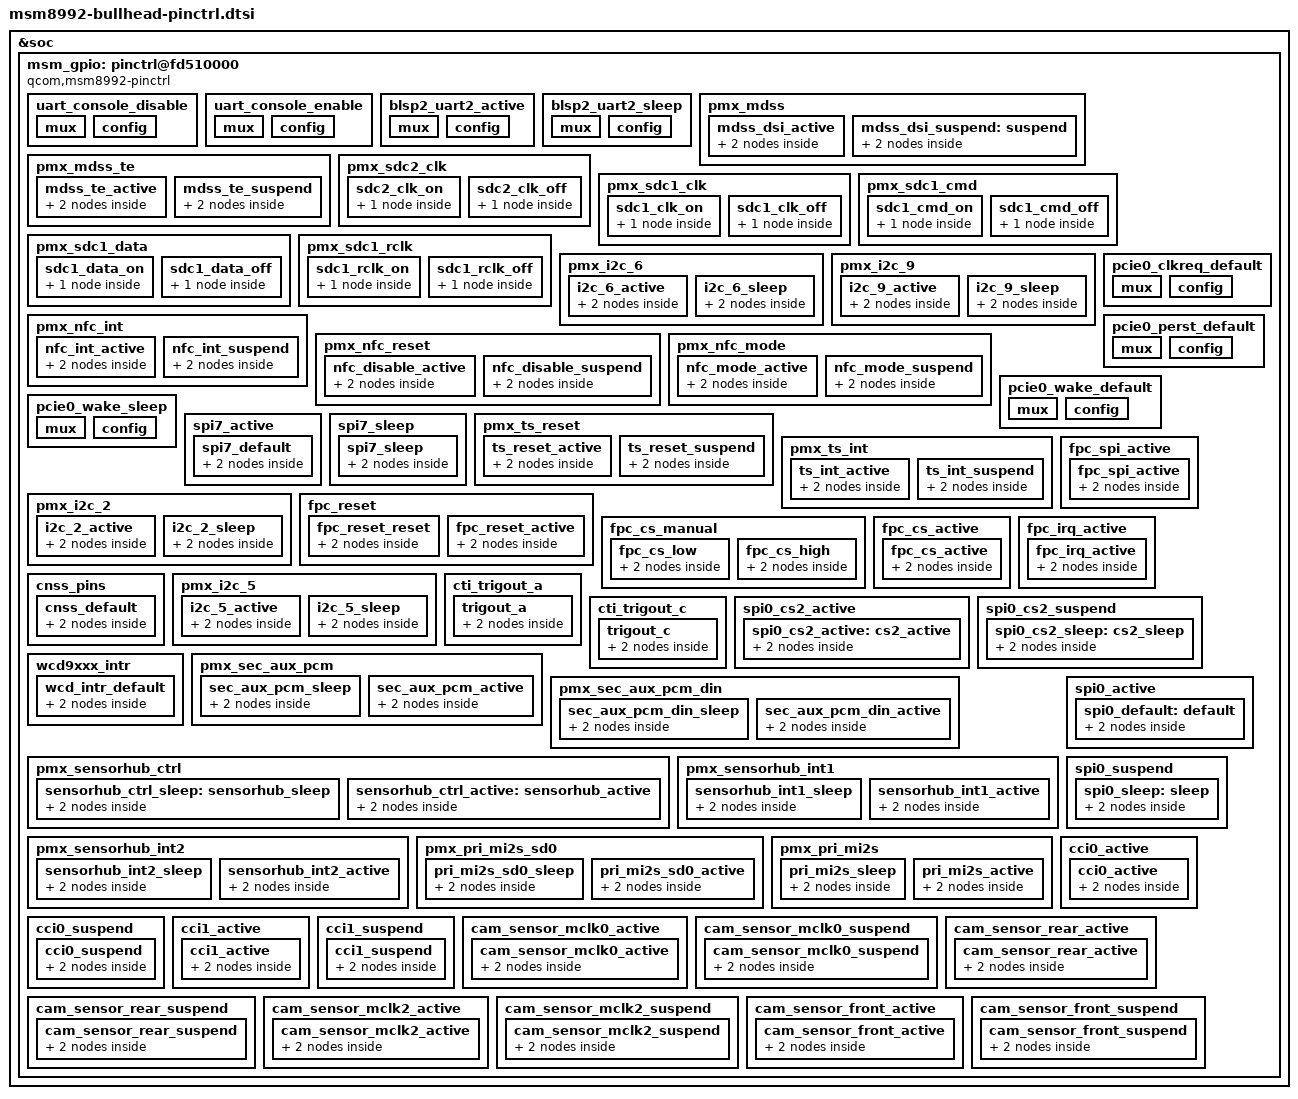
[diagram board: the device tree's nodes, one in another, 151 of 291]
/* Copyright (c) 2015, LGE Inc. All rights reserved.
 * Copyright (c) 2013-2015, The Linux Foundation. All rights reserved.
 *
 * This program is free software; you can redistribute it and/or modify
 * it under the terms of the GNU General Public License version 2 and
 * only version 2 as published by the Free Software Foundation.
 *
 * This program is distributed in the hope that it will be useful,
 * but WITHOUT ANY WARRANTY; without even the implied warranty of
 * MERCHANTABILITY or FITNESS FOR A PARTICULAR PURPOSE.  See the
 * GNU General Public License for more details.
 */

&soc {
	msm_gpio: pinctrl@fd510000 {
		compatible = "qcom,msm8992-pinctrl";
		reg = <0xfd510000 0x4000>;
		interrupts = <0 208 0>;
		gpio-controller;
		#gpio-cells = <2>;
		interrupt-controller;
		#interrupt-cells = <2>;

		uart_console_disable: uart_console_disable {
			mux {
				pins = "gpio4", "gpio5";
				function = "blsp_uart2";
			};

			config {
				pins = "gpio4", "gpio5";
				drive-strength = <2>; /* 2 mA */
				bias-disable; /* No PULL */
			};
		};

		uart_console_enable: uart_console_enable {
			mux {
				pins = "gpio4", "gpio5";
				function = "blsp_uart2";
			};

			config {
				pins = "gpio4", "gpio5";
				drive-strength = <2>; /* 2 mA */
				bias-disable; /* No PULL */
			};
		};


		blsp2_uart2_active: blsp2_uart2_active {
			mux {
				pins = "gpio45", "gpio46", "gpio47", "gpio48";
				function = "gpio";
			};

			config {
				pins = "gpio45", "gpio46", "gpio47", "gpio48";
				drive-strength = <16>; /* 16 mA */
				bias-disable; /* No PULL */
			};
		};

		blsp2_uart2_sleep: blsp2_uart2_sleep {
			mux {
				pins = "gpio45", "gpio46", "gpio47", "gpio48";
				function = "gpio";
			};

			config {
				pins = "gpio45", "gpio46", "gpio47", "gpio48";
				drive-strength = <2>; /* 2 mA */
				bias-disable; /* No PULL */
			};
		};


		pmx_mdss {
			mdss_dsi_active: mdss_dsi_active {
				mux {
					pins = "gpio78", "gpio89", "gpio90";
					function = "gpio";
				};

				config {
					pins = "gpio78", "gpio89", "gpio90";
					drive-strength = <8>; /* 8 mA */
					bias-disable; /* No PULL */
				};
			};

			mdss_dsi_suspend: suspend {
				mux {
					pins = "gpio78", "gpio89", "gpio90";
					function = "gpio";
				};

				config {
					pins = "gpio78", "gpio89", "gpio90";
					drive-strength = <2>; /* 2 mA */
					bias-pull-down; /* PULL DOWN */
				};
			};
		};

		pmx_mdss_te {
			mdss_te_active: mdss_te_active {
				mux {
					pins = "gpio10";
					function = "mdp_vsync";
				};

				config {
					pins = "gpio10";
					drive-strength = <2>; /* 2 mA */
					bias-pull-down = <0>; /* PULL DOWN */
				};
			};

			mdss_te_suspend: mdss_te_suspend {
				mux {
					pins = "gpio10";
					function = "mdp_vsync";
				};

				config {
					pins = "gpio10";
					drive-strength = <2>; /* 2 mA */
					bias-pull-down; /* PULL DOWN */
				};
			};
		};

		pmx_sdc2_clk {
			sdc2_clk_on: sdc2_clk_on {
				config {
					pins = "sdc2_clk";
					drive-strength = <16>; /* 10 mA */
					bias-disable; /* No PULL */
				};
			};
			sdc2_clk_off: sdc2_clk_off {
				config {
					pins = "sdc2_clk";
					drive-strength = <2>; /* 2 mA */
					bias-disable; /* No PULL */
				};
			};
		};

		pmx_sdc1_clk {
			sdc1_clk_on: sdc1_clk_on {
				config {
					pins = "sdc1_clk";
					drive-strength = <16>; /* 16 mA */
					bias-disable; /* No PULL */
				};
			};

			sdc1_clk_off: sdc1_clk_off {
				config {
					pins = "sdc1_clk";
					drive-strength = <2>; /* 2 mA */
					bias-disable; /* No PULL */
				};
			};
		};

		pmx_sdc1_cmd {
			sdc1_cmd_on: sdc1_cmd_on {
				config {
					pins = "sdc1_cmd";
					bias-pull-up; /* PULL UP */
					drive-strength = <8>; /* 8 mA */
				};
			};

			sdc1_cmd_off: sdc1_cmd_off {
				config {
					pins = "sdc1_cmd";
					bias-pull-up = <0x3>; /* PULL UP */
					drive-strength = <2>; /* 2 mA */
				};
			};
		};

		pmx_sdc1_data {
			sdc1_data_on: sdc1_data_on {
				config {
					pins = "sdc1_data";
					bias-pull-up; /* PULL UP */
					drive-strength = <8>; /* 10 mA */
				};
			};

			sdc1_data_off: sdc1_data_off {
				config {
					pins = "sdc1_data";
					bias-pull-up; /* PULL UP */
					drive-strength = <2>; /* 2 mA */
				};
			};
		};

		pmx_sdc1_rclk {
			sdc1_rclk_on: sdc1_rclk_on {
				config {
					pins = "sdc1_rclk";
					bias-pull-down; /* PULL DOWN */
				};
			};

			sdc1_rclk_off: sdc1_rclk_off {
				config {
					pins = "sdc1_rclk";
					bias-pull-down; /* PULL DOWN */
				};
			};
		};

		pmx_i2c_6 {
			i2c_6_active: i2c_6_active {
				mux {
					pins = "gpio27", "gpio28";
					function = "blsp_i2c6";
				};

				config {
					pins = "gpio27", "gpio28";
					drive-strength = <2>; /* 2 mA */
					bias-disable; /* No PULL */
				};
			};

			i2c_6_sleep: i2c_6_sleep {
				mux {
					pins = "gpio27", "gpio28";
					function = "blsp_i2c6";
				};

				config {
					pins = "gpio27", "gpio28";
					drive-strength = <2>; /* 2 mA */
					bias-disable; /* No PULL */
				};
			};

		};

		pmx_i2c_9 {
			i2c_9_active: i2c_9_active {
				mux {
					pins = "gpio51", "gpio52";
					function = "blsp_i2c9";
				};

				config {
					pins = "gpio51", "gpio52";
					drive-strength = <2>; /* 2 mA */
					bias-disable; /* No PULL */
				};
			};

			i2c_9_sleep: i2c_9_sleep {
				mux {
					pins = "gpio51", "gpio52";
					function = "blsp_i2c9";
				};

				config {
					pins = "gpio51", "gpio52";
					drive-strength = <2>; /* 2 mA */
					bias-disable; /* No PULL */
				};
			};

		};

		pmx_nfc_int {
			nfc_int_active: nfc_int_active {
				mux {
					pins = "gpio29";
					function = "gpio";
				};

				config {
					drive-strength = <2>; /* 2 mA */
					bias-disable; /* No PULL */
				};
			};

			nfc_int_suspend: nfc_int_suspend {
				mux {
					pins = "gpio29";
					function = "gpio";
				};

				config {
					drive-strength = <2>; /* 2 mA */
					bias-disable; /* No PULL */
				};
			};
		};

		pmx_nfc_reset {
			nfc_disable_active: nfc_disable_active {
				mux {
					pins = "gpio30";
					function = "gpio";
				};

				config {
					drive-strength = <2>; /* 2 mA */
					bias-pull-up; /* PULL UP */
				};
			};

			nfc_disable_suspend: nfc_disable_suspend {
				mux {
					pins = "gpio30";
					function = "gpio";
				};

				config {
					drive-strength = <2>; /* 2 mA */
					bias-disable; /* No PULL */
				};
			};
		};

		pmx_nfc_mode {
			nfc_mode_active: nfc_mode_active {
				mux {
					pins = "gpio39";
					function = "gpio";
				};

				config {
					drive-strength = <2>; /* 2 mA */
					bias-disable; /* No PULL */
				};
			};

			nfc_mode_suspend: nfc_mode_suspend {
				mux {
					pins = "gpio39";
					function = "gpio";
				};

				config {
					drive-strength = <2>; /* 2 mA */
					bias-disable; /* No PULL */
				};
			};
		};

		pcie0_clkreq_default: pcie0_clkreq_default {
			mux {
				pins = "gpio36";
				function = "pci_e1";
			};

			config {
				pins = "gpio36";
				drive-strength = <2>; /* 2 mA */
				bias-pull-up; /* PULL UP */
			};
		};

		pcie0_perst_default: pcie0_perst_default {
			mux {
				pins = "gpio35";
				function = "gpio";
			};

			config {
				pins = "gpio35";
				drive-strength = <2>; /* 2 mA */
				bias-pull-down; /* PULL DOWN */
			};
		};

		pcie0_wake_default: pcie0_wake_default {
			mux {
				pins = "gpio37";
				function = "gpio";
			};

			config {
				pins = "gpio37";
				drive-strength = <2>; /* 2 mA */
				bias-pull-down; /* PULL DOWN */
			};
		};

		pcie0_wake_sleep: pcie0_wake_sleep {
			mux {
				pins = "gpio37";
				function = "gpio";
			};

			config {
				pins = "gpio37";
				drive-strength = <2>; /* 2 mA */
				bias-disable; /* No PULL */
			};
		};


		spi7_active {
			spi7_default: spi7_default {
				mux {
					pins = "gpio41", "gpio42", "gpio44";
					function = "blsp_spi7";
				};

				config {
					pins = "gpio41", "gpio42", "gpio44";
					drive-strength = <12>; /* 12 mA */
					bias-disable; /* No PULL */
				};
			};
		};

		spi7_sleep {
			spi7_sleep: spi7_sleep {
				mux {
					pins = "gpio41", "gpio42", "gpio44";
					function = "blsp_spi7";
				};

				config {
					pins = "gpio41", "gpio42", "gpio44";
					drive-strength = <2>; /* 2 mA */
					bias-pull-down; /* PULL DOWN */
				};
			};
		};

		pmx_ts_reset {
			ts_reset_active: ts_reset_active {
				mux {
					pins = "gpio8";
					function = "gpio";
				};

				config {
					pins = "gpio8";
					drive-strength = <2>; /* 2 mA */
					bias-disable; /* No PULL */
				};
			};

			ts_reset_suspend: ts_reset_suspend {
				mux {
					pins = "gpio8";
					function = "gpio";
				};

				config {
					pins = "gpio8";
					drive-strength = <2>; /* 2 mA */
					bias-disable; /* No PULL */
				};
			};
		};

		pmx_ts_int {
			ts_int_active: ts_int_active {
				mux {
					pins = "gpio22";
					function = "gpio";
				};

				config {
					pins = "gpio22";
					drive-strength = <2>; /* 2 mA */
					bias-disable; /* No PULL */
				};
			};

			ts_int_suspend: ts_int_suspend {
				mux {
					pins = "gpio22";
					function = "gpio";
				};

				config {
					pins = "gpio22";
					drive-strength = <2>; /* 2 mA */
					bias-disable; /* No PULL */
				};
			};
		};

		pmx_i2c_2 {
			i2c_2_active: i2c_2_active {
				mux {
					pins = "gpio6", "gpio7";
					function = "blsp_i2c2";
				};

				config {
					pins = "gpio6", "gpio7";
					drive-strength = <6>; /* 6 mA */
					bias-disable; /* No PULL */
				};
			};

			i2c_2_sleep: i2c_2_sleep {
				mux {
					pins = "gpio6", "gpio7";
					function = "blsp_i2c2";
				};

				config {
					pins = "gpio6", "gpio7";
					drive-strength = <2>; /* 2 mA */
					bias-disable; /* No PULL */
				};
			};
		};

		fpc_spi_active {
			fpc_spi_active: fpc_spi_active {
				mux {
					pins =  "gpio53", "gpio54", "gpio55", "gpio56";
					function = "blsp_spi10";
				};

				config {
					pins =  "gpio53", "gpio54", "gpio55", "gpio56";
					drive-strength = <2>; /* 2 mA */
					bias-disable; /* No PULl */
				};
			};
		};

		fpc_reset {
			fpc_reset_reset: fpc_reset_reset {
				mux {
					pins = "gpio62";
					function = "blsp_spi2_cs1";
				};

				config {
					pins = "gpio62";
					drive-strength = <12>; /* 12 mA */
					bias-pull-down; /* PULL DOWN */
					output-low;
				};
			};

			fpc_reset_active: fpc_reset_active {
				mux {
					pins = "gpio62";
					function = "blsp_spi2_cs1";
				};

				config {
					pins = "gpio62";
					drive-strength = <12>; /* 12 mA */
					bias-pull-down; /* PULL DOWN */
					output-high;
				};
			};

		};

		fpc_cs_manual {
			fpc_cs_low: fpc_cs_low {
				mux {
					pins = "gpio55";
					function = "gpio";
				};

				config {
					pins = "gpio55";
					drive-strength = <1>; /* 1 mA */
					bias-pull-down; /* PULL DOWN */
					output-low;
				};
			};

			fpc_cs_high: fpc_cs_high {
				mux {
					pins = "gpio55";
					function = "gpio";
				};

				config {
					pins = "gpio55";
					drive-strength = <12>; /* 12 mA */
					bias-pull-down; /* PULL DOWN */
					output-high;
				};
			};

		};

		fpc_cs_active {
			fpc_cs_active: fpc_cs_active {
				mux {
					pins = "gpio55";
					function = "gpio";
				};

				config {
					pins = "gpio55";
					drive-strength = <12>; /* 12 mA */
					bias-pull-down; /* PULL DOWN */
				};
			};
		};

		fpc_irq_active {
			fpc_irq_active: fpc_irq_active {
				mux {
					pins = "gpio61";
					function = "gpio";
				};

				config {
					pins = "gpio61";
					drive-strength = <12>; /* 12 mA */
					bias-pull-down; /* PULL DOWN */
					input-enable;
				};
			};
		};

		cnss_pins {
			cnss_default: cnss_default {
				mux {
					pins = "gpio113";
					function = "gpio";
				};

				config {
					pins = "gpio113";
					drive-strength = <16>; /* 16 mA */
					bias-pull-down; /* PULL DOWN */
				};
			};
		};

		pmx_i2c_5 {
			i2c_5_active: i2c_5_active {
				mux {
					pins = "gpio83", "gpio84";
					function = "blsp_i2c11";
				};

				config {
					pins = "gpio83", "gpio84";
					drive-strength = <2>; /* 2 mA */
					bias-disable; /* No PULL */
				};
			};

			i2c_5_sleep: i2c_5_sleep {
				mux {
					pins = "gpio83", "gpio84";
					function = "blsp_i2c11";
				};

				config {
					pins = "gpio83", "gpio84";
					drive-strength = <2>; /* 2 mA */
					bias-disable; /* No PULL */
				};
			};
		};

		cti_trigout_a {
			trigout_a: trigout_a {
				mux {
					pins = "gpio56";
					function = "gpio";
				};

				config {
					pins = "gpio56";
					drive-strength = <2>; /* 2 mA */
					bias-disable; /* No PULL */
				};
			};
		};

		cti_trigout_c {
			trigout_c: trigout_c {
				mux {
					pins = "gpio41";
					function = "gpio";
				};

				config {
					pins = "gpio41";
					drive-strength = <2>; /* 2 mA */
					bias-disable; /* No PULL */
				};
			};
		};


		spi0_cs2_active {
			spi0_cs2_active: cs2_active {
				mux {
					pins = "gpio9";
					function = "blsp_spi1";
				};

				config {
					pins = "gpio9";
					drive-strength = <2>; /* 2 mA */
					bias-disable = <0>; /* No PULL */
				};
			};
		};

		spi0_cs2_suspend {
			spi0_cs2_sleep: cs2_sleep {
				mux {
					pins = "gpio9";
					function = "blsp_spi1";
				};

				config {
					pins = "gpio9";
					drive-strength = <2>; /* 2 mA */
					bias-disable = <0>; /* No PULL */
				};
			};
		};

		wcd9xxx_intr {
			wcd_intr_default: wcd_intr_default {
				mux {
					pins = "gpio72";
					function = "spkr_i2s";
				};

				config {
					pins = "gpio72";
					drive-strength = <2>; /* 2 mA */
					bias-pull-down; /* PULL Down */
					input-enable;
				};
			};
		};

		pmx_sec_aux_pcm {
			sec_aux_pcm_sleep: sec_aux_pcm_sleep {
				mux {
					pins = "gpio79", "gpio80", "gpio82";
					function = "gpio";
				};

				config {
					pins = "gpio79", "gpio80", "gpio82";
					drive-strength = <2>; /* 2 mA */
					bias-pull-down; /* PULL DOWN */
				};
			};

			sec_aux_pcm_active: sec_aux_pcm_active {
				mux {
					pins = "gpio79", "gpio80", "gpio82";
					function = "gpio";
				};

				config {
					pins = "gpio79", "gpio80", "gpio82";
					drive-strength = <8>; /* 8 mA */
					bias-pull-down; /* PULL DOWN */
					output-high;
				};
			};
		};

		pmx_sec_aux_pcm_din {
			sec_aux_pcm_din_sleep: sec_aux_pcm_din_sleep {
				mux {
					pins = "gpio81";
					function = "gpio";
				};

				config {
					pins = "gpio81";
					drive-strength = <2>; /* 2 mA */
					bias-pull-down; /* PULL DOWN */
				};
			};

			sec_aux_pcm_din_active: sec_aux_pcm_din_active {
				mux {
					pins = "gpio81";
					function = "gpio";
				};

				config {
					pins = "gpio81";
					drive-strength = <8>; /* 8 mA */
					bias-disable; /* No PULL */
				};
			};
		};


		pmx_sensorhub_ctrl {
			sensorhub_ctrl_sleep: sensorhub_sleep {
				mux {
					pins = "gpio59", "gpio60", "gpio43";
					function = "gpio";
				};

				config {
					pins = "gpio59", "gpio60", "gpio43";
					drive-strength = <2>; /* 2 mA */
					bias-disable; /* No PULL */
				};
			};

			sensorhub_ctrl_active: sensorhub_active {
				mux {
					pins = "gpio59", "gpio60", "gpio43";
					function = "gpio";
				};

				config {
					pins = "gpio59", "gpio60", "gpio43";
					drive-strength = <2>; /* 2 mA */
					bias-disable; /* No PULL */
				};
			};
		};

		pmx_sensorhub_int1 {
			sensorhub_int1_sleep: sensorhub_int1_sleep {
				mux {
					pins = "gpio65";
					function = "gpio";
				};

				config {
					pins = "gpio65";
					drive-strength = <2>; /* 2 mA */
					bias-disable; /* No PULL */
				};
			};

			sensorhub_int1_active: sensorhub_int1_active {
				mux {
					pins = "gpio65";
					function = "gpio";
				};

				config {
					pins = "gpio65";
					drive-strength = <2>; /* 2 mA */
					bias-disable; /* No PULL */
				};
			};
		};

		pmx_sensorhub_int2 {
			sensorhub_int2_sleep: sensorhub_int2_sleep {
				mux {
					pins = "gpio66";
					function = "gpio";
				};

				config {
					pins = "gpio66";
					drive-strength = <2>; /* 2 mA */
					bias-disable; /* No PULL */
				};
			};

			sensorhub_int2_active: sensorhub_int2_active {
				mux {
					pins = "gpio66";
					function = "gpio";
				};

				config {
					pins = "gpio66";
					drive-strength = <2>; /* 2 mA */
					bias-pull-up; /* PULL UP */
				};
			};
		};

		spi0_active {
			spi0_default: default {
				mux {
					pins = "gpio0", "gpio1", "gpio3";
					function = "blsp_spi1";
				};

				config {
					pins = "gpio0", "gpio1", "gpio3";
					drive-strength = <12>; /* 12 mA */
					bias-disable = <0>; /* No PULL */
				};
			};
		};

		spi0_suspend {
			spi0_sleep: sleep {
				mux {
					pins = "gpio0", "gpio1", "gpio3";
					function = "blsp_spi1";
				};

				config {
					pins = "gpio0", "gpio1", "gpio3";
					drive-strength = <2>; /* 2 mA */
					bias-pull-down; /* PULL DOWN */
				};
			};
		};

		pmx_pri_mi2s_sd0 {
			pri_mi2s_sd0_sleep: pri_mi2s_sd0_sleep {
				mux {
					pins = "gpio67";
					function = "pri_mi2s";
				};

				config {
					pins = "gpio67";
					drive-strength = <2>; /* 2 mA */
					bias-pull-down;	/* PULL DOWN */
				};
			};

			pri_mi2s_sd0_active: pri_mi2s_sd0_active {
				mux {
					pins = "gpio67";
					function = "pri_mi2s";
				};

				config {
					pins = "gpio67";
					drive-strength = <2>; /* 2 mA */
					bias-disable; /* No PULL */
				};
			};
		};

		pmx_pri_mi2s {
			pri_mi2s_sleep: pri_mi2s_sleep {
				mux {
					pins = "gpio65", "gpio66";
					function = "pri_mi2s";
				};

				config {
					pins = "gpio65", "gpio66";
					drive-strength = <2>; /* 2 mA */
					bias-pull-down;	/* PULL DOWN */
				};
			};

			pri_mi2s_active: pri_mi2s_active {
				mux {
					pins = "gpio65", "gpio66";
					function = "pri_mi2s";
				};

				config {
					pins = "gpio65", "gpio66";
					drive-strength = <2>; /* 2 mA */
					bias-disable; /* No PULL */
					output-high;
				};
			};
		};

		/* pin-ctrl for camera sensor */
		cci0_active {
			cci0_active: cci0_active {
				mux {
					pins = "gpio17", "gpio18";
					function = "cci_i2c0";
				};

				config {
					pins = "gpio17", "gpio18";
					drive-strength = <2>; /* 2 mA */
					bias-disable; /* No PULL */
				};
			};
		};

		cci0_suspend {
			cci0_suspend: cci0_suspend {
				mux {
					pins = "gpio17", "gpio18";
					function = "cci_i2c0";
				};

				config {
					pins = "gpio17", "gpio18";
					drive-strength = <2>; /* 2 mA */
					bias-disable; /* No PULL */
				};
			};
		};


		cci1_active {
			cci1_active: cci1_active {
				mux {
					pins = "gpio19", "gpio20";
					function = "cci_i2c1";
				};

				config {
					pins = "gpio19", "gpio20";
					drive-strength = <2>; /* 2 mA */
					bias-disable; /* No PULL */
				};
			};
		};

		cci1_suspend {
			cci1_suspend: cci1_suspend {
				mux {
					pins = "gpio19", "gpio20";
					function = "cci_i2c1";
				};

				config {
					pins = "gpio19", "gpio20";
					drive-strength = <2>; /* 2 mA */
					bias-disable; /* No PULL */
				};
			};
		};

		cam_sensor_mclk0_active {
			cam_sensor_mclk0_active: cam_sensor_mclk0_active {
				mux {
					pins = "gpio13";
					function = "cam_mclk0";
				};

				config {
					pins = "gpio13";
					drive-strength = <2>; /* 2 mA */
					bias-disable; /* No PULL */
				};
			};
		};


		cam_sensor_mclk0_suspend {
			cam_sensor_mclk0_suspend: cam_sensor_mclk0_suspend {
				mux {
					pins = "gpio13";
					function = "cam_mclk0";
				};

				config {
					pins = "gpio13";
					drive-strength = <2>; /* 2 mA */
					bias-pull-down; /* PULL Down */
				};
			};
		};


		cam_sensor_rear_active {
			cam_sensor_rear_active: cam_sensor_rear_active {
				mux {
					pins = "gpio92";
					function = "gpio";
				};

				config {
					pins = "gpio92";
					drive-strength = <2>; /* 2 mA */
					bias-disable; /* No PULL */
				};
			};
		};

		cam_sensor_rear_suspend {
			cam_sensor_rear_suspend: cam_sensor_rear_suspend {
				mux {
					pins = "gpio92";
					function = "gpio";
				};

				config {
					pins = "gpio92";
					drive-strength = <2>; /* 2 mA */
					bias-disable; /* No PULL */
				};
			};
		};

		cam_sensor_mclk2_active {
			cam_sensor_mclk2_active: cam_sensor_mclk2_active {
				mux {
					pins = "gpio15";
					function = "cam_mclk2";
				};

				config {
					pins = "gpio15";
					drive-strength = <2>; /* 2 mA */
					bias-disable; /* No PULL */
				};
			};
		};

		cam_sensor_mclk2_suspend {
			cam_sensor_mclk2_suspend: cam_sensor_mclk2_suspend {
				mux {
					pins = "gpio15";
					function = "cam_mclk2";
				};

				config {
					pins = "gpio15";
					drive-strength = <2>; /* 2 mA */
					bias-pull-down; /* No PULL */
				};
			};
		};


		cam_sensor_front_active {
			cam_sensor_front_active: cam_sensor_front_active {
				mux {
					pins = "gpio104";
					function = "gpio";
				};

				config {
					pins = "gpio104";
					drive-strength = <2>; /* 2 mA */
					bias-pull-down; /* No PULL */
				};
			};
		};

		cam_sensor_front_suspend {
			cam_sensor_front_suspend: cam_sensor_front_suspend {
				mux {
					pins = "gpio104";
					function = "gpio";
				};

				config {
					pins = "gpio104";
					drive-strength = <2>; /* 2 mA */
					bias-pull-down; /* No PULL */
				};
			};
		};
	};
};
